# ATSAMC20N17A register map
Vendor: Microchip Technology; Series: SAMC20; File version: 0
CPU: CM0+ r0p0, selectable endian, MPU, no FPU, VTOR, 2 interrupt priority bits
Registers are 32-bit, read-write, reset 0x0 unless marked. A register's access mark holds for its fields unless they carry their own. Offsets are from the block's base; [hi:lo] are bit positions; lines under a group give offsets from that group; {n}, {i} and the like mark numbered series.

## FREQM — Frequency Meter
Base 0x40002C00; register names take the prefix FREQM_
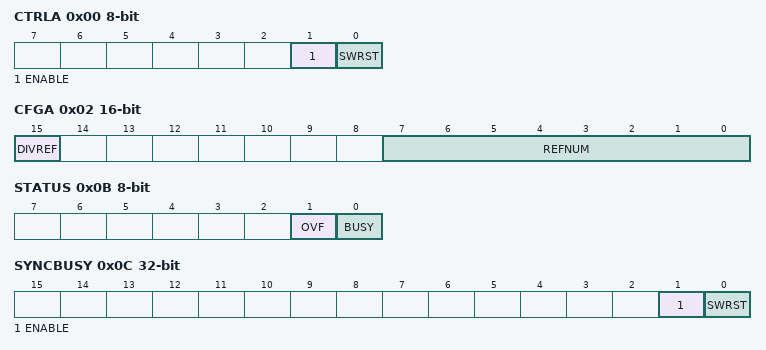
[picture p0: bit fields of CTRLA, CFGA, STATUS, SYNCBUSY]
0x00 CTRLA 8-bit — Control A Register
  [1] ENABLE
  [0] SWRST — Software Reset
0x01 CTRLB 8-bit wo — Control B Register
  [0] START — Start Measurement
0x02 CFGA 16-bit — Config A register
  [15] DIVREF — Divide Reference Clock
  [7:0] REFNUM — Number of Reference Clock Cycles
0x08 INTENCLR 8-bit — Interrupt Enable Clear Register
  [0] DONE — Measurement Done Interrupt Enable
0x09 INTENSET 8-bit — Interrupt Enable Set Register
  [0] DONE — Measurement Done Interrupt Enable
0x0A INTFLAG 8-bit — Interrupt Flag Register
  [0] DONE — Measurement Done
0x0B STATUS 8-bit
  [1] OVF — Sticky Count Value Overflow
  [0] BUSY — FREQM Status
0x0C SYNCBUSY ro — Synchronization Busy Register
  [1] ENABLE
  [0] SWRST — Software Reset
0x10 VALUE ro — Count Value Register
  [23:0] VALUE — Measurement Value

## GCLK — Generic Clock Generator
Base 0x40001C00; register names take the prefix GCLK_
0x00 CTRLA 8-bit — Control
  [0] SWRST — Software Reset
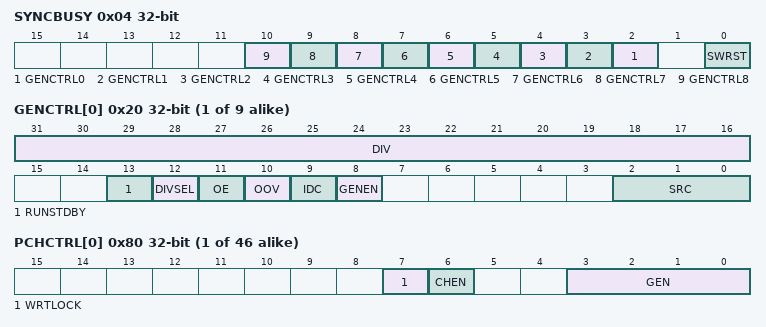
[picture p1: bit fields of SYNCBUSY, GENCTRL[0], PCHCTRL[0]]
0x04 SYNCBUSY ro — Synchronization Busy
  [n+2] GENCTRL{n} (n=0..8) — Generic Clock Generator Control {n} Synchronization Busy bits
    1=GCLK0 (Generic clock generator 0); 2=GCLK1 (Generic clock generator 1); 4=GCLK2 (Generic clock generator 2); 8=GCLK3 (Generic clock generator 3); 16=GCLK4 (Generic clock generator 4); 32=GCLK5 (Generic clock generator 5); 64=GCLK6 (Generic clock generator 6); 128=GCLK7 (Generic clock generator 7); 0x100=GCLK8 (Generic clock generator 8)
  [0] SWRST — Software Reset Synchroniation Busy bit
{0x20+4i} GENCTRL[{i}] (i=0..8) — Generic Clock Generator Control
  [31:16] DIV — Division Factor
  [13] RUNSTDBY — Run in Standby
  [12] DIVSEL — Divide Selection
    0=DIV1 (Divide input directly by divider factor); 1=DIV2 (Divide input by 2^(divider factor+ 1))
  [11] OE — Output Enable
  [10] OOV — Output Off Value
  [9] IDC — Improve Duty Cycle
  [8] GENEN — Generic Clock Generator Enable
  [2:0] SRC — Source Select
    0=XOSC (XOSC oscillator output); 1=GCLKIN (Generator input pad); 2=GCLKGEN1 (Generic clock generator 1 output); 3=OSCULP32K (OSCULP32K oscillator output); 4=OSC32K (OSC32K oscillator output); 5=XOSC32K (XOSC32K oscillator output); 6=OSC48M (OSC48M oscillator output); 7=DPLL96M (DPLL96M output)
{0x80+4i} PCHCTRL[{i}] (i=0..45) — Peripheral Clock Control
  [7] WRTLOCK — Write Lock
  [6] CHEN — Channel Enable
  [3:0] GEN — Generic Clock Generator
    {v}=GCLK{v} (Generic clock generator {v}) (v=0..8)

## HMATRIXHS — HSB Matrix
Base 0x4100A000; register names take the prefix HMATRIXB_
{0x0+4i} MCFG[{i}] (i=0..15) reset 0x2 — Master Configuration
  [2:0] ULBT — Undefined Length Burst Type
    0=INFINITE (Infinite Length); 1=SINGLE (Single Access); 2=FOUR_BEAT (Four Beat Burst); 3=EIGHT_BEAT (Eight Beat Burst); 4=SIXTEEN_BEAT (Sixteen Beat Burst)
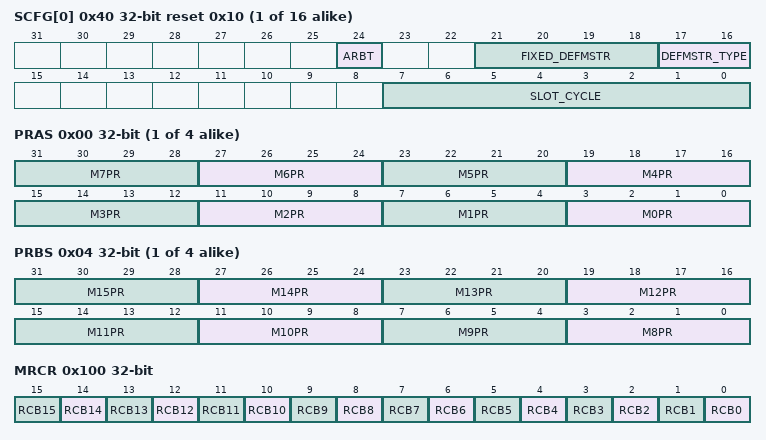
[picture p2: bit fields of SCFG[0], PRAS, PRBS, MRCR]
{0x40+4i} SCFG[{i}] (i=0..15) reset 0x10 — Slave Configuration
  [24] ARBT — Arbitration Type
    0=ROUND_ROBIN (Round-Robin Arbitration); 1=FIXED_PRIORITY (Fixed Priority Arbitration)
  [21:18] FIXED_DEFMSTR — Fixed Index of Default Master
  [17:16] DEFMSTR_TYPE — Default Master Type
    0=NO_DEFAULT (No Default Master. At the end of current slave access, if no other master request is pending, the slave is deconnected from all masters. This resusts in having a one cycle latency for the first transfer of a burst.); 1=LAST_DEFAULT (Last Default Master At the end of current slave access, if no other master request is pending, the slave stay connected with the last master havingaccessed it.This resusts in not having the one cycle latency when the last master re-trying access on the slave.); 2=FIXED_DEFAULT (Fixed Default Master At the end of current slave access, if no other master request is pending, the slave connects with fixed master which numberis in FIXED_DEFMSTR register.This resusts in not having the one cycle latency when the fixed master re-trying access on the slave.)
  [7:0] SLOT_CYCLE — Maximum Number of Allowed Cycles for a Burst
{0x80+8i} PRS[{i}] (i=0..3) group
  0x00 PRAS — Priority A for Slave
    [4n+3:4n] M{n}PR (n=0..7) — Master {n} Priority
  0x04 PRBS — Priority B for Slave
    [4n-29:4n-32] M{n}PR (n=8..15) — Master {n} Priority
0x100 MRCR — Master Remap Control
  [all] fields
    0=DIS (Disable remapped address decoding for master); 1=ENA (Enable remapped address decoding for master)
  [n] RCB{n} (n=0..15) — Remap Command Bit for Master {n}
{0x110+4i} SFR[{i}] (i=0..15) — Special Function
  [31:0] SFR — Special Function Register
